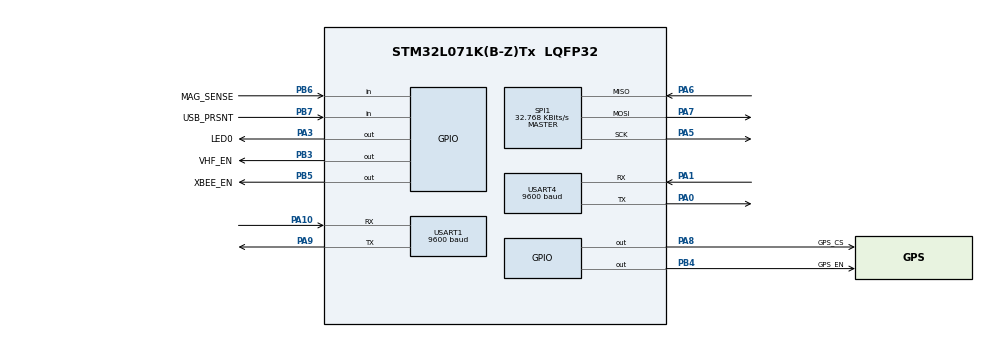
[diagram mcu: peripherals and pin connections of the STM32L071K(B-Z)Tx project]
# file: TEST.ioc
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Mcu.Family=STM32L0
Mcu.Name=STM32L071K(B-Z)Tx
Mcu.Package=LQFP32
NVIC.RTC_IRQn=true\:0\:0\:false\:false\:true\:true\:true
NVIC.SPI1_IRQn=true\:0\:0\:false\:false\:true\:true\:true
NVIC.TIM2_IRQn=true\:0\:0\:false\:false\:true\:true\:true
NVIC.USART1_IRQn=true\:0\:0\:false\:false\:true\:true\:true
NVIC.USART4_5_IRQn=true\:0\:0\:false\:false\:true\:true\:true
PA0.Mode=Asynchronous
PA0.Signal=USART4_TX
PA1.Mode=Asynchronous
PA1.Signal=USART4_RX
PA10.Mode=Asynchronous
PA10.Signal=USART1_RX
PA13.Mode=Serial_Wire
PA13.Signal=SYS_SWDIO
PA14.Mode=Serial_Wire
PA14.Signal=SYS_SWCLK
PA3.GPIO_Label=LED0
PA3.Signal=GPIO_Output
PA5.Mode=Full_Duplex_Master
PA5.Signal=SPI1_SCK
PA6.Mode=Full_Duplex_Master
PA6.Signal=SPI1_MISO
PA7.Mode=Full_Duplex_Master
PA7.Signal=SPI1_MOSI
PA8.GPIO_Label=GPS_CS
PA8.Signal=GPIO_Output
PA9.Mode=Asynchronous
PA9.Signal=USART1_TX
PB3.GPIO_Label=VHF_EN
PB3.Signal=GPIO_Output
PB4.GPIO_Label=GPS_EN
PB4.Signal=GPIO_Output
PB5.GPIO_Label=XBEE_EN
PB5.Signal=GPIO_Output
PB6.GPIO_Label=MAG_SENSE
PB6.Signal=GPIO_Input
PB7.GPIO_Label=USB_PRSNT
PB7.Signal=GPIO_Input
PC14-OSC32_IN.Mode=LSE-External-Oscillator
PC14-OSC32_IN.Signal=RCC_OSC32_IN
PC15-OSC32_OUT.Mode=LSE-External-Oscillator
PC15-OSC32_OUT.Signal=RCC_OSC32_OUT
ProjectManager.HeapSize=0x200
ProjectManager.StackSize=0x400
ProjectManager.TargetToolchain=MDK-ARM V5
RCC.AHBFreq_Value=262144
RCC.APB1Freq_Value=262144
RCC.APB1TimFreq_Value=262144
RCC.APB2Freq_Value=262144
RCC.APB2TimFreq_Value=262144
RCC.HCLKFreq_Value=262144
RCC.HSI16_VALUE=16000000
RCC.HSI_VALUE=16000000
RCC.MSIClockRange=RCC_MSIRANGE_2
RCC.MSI_VALUE=262144
RCC.RTCClockSelection=RCC_RTCCLKSOURCE_LSE
RCC.RTCClockSelectionVirtual=RCC_RTCCLKSOURCE_LSE
RCC.SYSCLKFreq_VALUE=262144
RCC.VCOOutputFreq_Value=48000000
RTC.Alarm=RTC_ALARM_A
SPI1.BaudRatePrescaler=SPI_BAUDRATEPRESCALER_8
SPI1.CalculateBaudRate=32.768 KBits/s
SPI1.Direction=SPI_DIRECTION_2LINES
SPI1.Mode=SPI_MODE_MASTER
SPI1.VirtualType=VM_MASTER
USART1.BaudRate=9600
USART1.VirtualMode-Asynchronous=VM_ASYNC
USART4.BaudRate=9600
USART4.SwapParam=ADVFEATURE_SWAP_ENABLE
USART4.VirtualMode-Asynchronous=VM_ASYNC
VP_RTC_VS_RTC_Activate.Mode=RTC_Enabled
VP_RTC_VS_RTC_Alarm_A_Intern.Mode=Alarm A
VP_RTC_VS_RTC_Calendar.Mode=RTC_Calendar
VP_TIM2_VS_ClockSourceINT.Mode=Internal
board=custom

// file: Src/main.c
/* USER CODE BEGIN Header */
/**
  ******************************************************************************
  * @file           : main.c
  * @brief          : Main program body
  ******************************************************************************
  * @attention
  *
  * <h2><center>&copy; Copyright (c) 2019 STMicroelectronics.
  * All rights reserved.</center></h2>
  *
  * This software component is licensed by ST under BSD 3-Clause license,
  * the "License"; You may not use this file except in compliance with the
  * License. You may obtain a copy of the License at:
  *                        opensource.org/licenses/BSD-3-Clause
  *
  ******************************************************************************
  */

#include "main.h"
#include "comport.h"
#include "globals.h"
#include "flash.h"
#include "xbee.h"
#include "timers.h"
#include "scheduler.h"
#include "lowpower.h"
#include <string.h>
int checkSchedule = 0;
int GPS_active = 0;
int XB_VHF_active = 0;

void SystemClock_Config(void);
static void MX_GPIO_Init(void);
static void MX_RTC_Init(void);
static void MX_SPI1_Init(void);
static void MX_TIM2_Init(void);
static void MX_USART1_UART_Init(void);
static void MX_USART4_UART_Init(void);

//Begin main
//------------------------------------------------------------------------------
int main(void)
	{
  //-- Initial MCU Configuration------------------------------------------------
  // Reset of all peripherals, Initializes the Flash interface and the Systick.
  LL_APB2_GRP1_EnableClock(LL_APB2_GRP1_PERIPH_SYSCFG);
  LL_APB1_GRP1_EnableClock(LL_APB1_GRP1_PERIPH_PWR);

  // Configure the system clock
  SystemClock_Config();

	__disable_irq();
  // Initialize all configured peripherals
  MX_GPIO_Init();
  MX_RTC_Init();
	RTC_initAlarm();
  MX_SPI1_Init();
  MX_TIM2_Init();
  MX_USART1_UART_Init();
	// Set up interrupts for the UART coms
	LL_USART_Disable(USART1);
	USART1->CR1 |= USART_CR1_RXNEIE;
	LL_USART_Enable(USART1);

#ifdef __LARGE_COLLAR_
  MX_USART4_UART_Init();
	LL_USART_Disable(USART4);
	USART4->CR1 |= USART_CR1_RXNEIE;
	LL_USART_Enable(USART4);
#endif

	// Enable these interrupts
	__enable_irq();

	// Init timers and alarms

	TIM2_init();

	//This small delay initializes the delay for further use
	TIM2_delay(1);

	//Ensure all devices are off
	GPS_GPSDisable();
	GPS_GPSCSHigh();
#ifdef __LARGE_COLLAR_
	XB_DisableXbee();
	VHF_DisableVHF();
#endif

	// Set unused pins low
	LPM_gpioInit();

	//-----------------
	// Main Variables
	// These vars are used as flags for the scheduler
	int GPS_active 	= 0;
	int XB_VHF_active 	= 0;

#ifndef __PRODUCTION_
	FLASH_Unlock();
	EEPROM_WriteByte(0x0A, 0x08080004);
	FLASH_Lock();
#endif

	//End of initialization, begin while loop
	//------------------------------------------------------------------------------
  while (1)
  {

		//Check for com port connected (should be while to hold device in this state)
		//----------------------------
		if(CC_ComPortPresent())
		{

			//Check for handshake from GUI
			if(CC_CheckForHandshake())
			{
				//Handshake completed, look for command, execute commands and loop
				while (CC_ComPortPresent())
				{
					CC_ExecuteCommand(CC_ParseCommand());
					break;
				}//While present
			}//Check handshake

		}//Comport present
		//Logic low hall effect sensor, this means no mag is present
		if( (MAG_SENSE_GPIO_Port->IDR & MAG_SENSE_Pin) != 0 )
		{
			if( checkSchedule == 1){
				scheduler( &GPS_active, &XB_VHF_active );
				checkSchedule = 0;
			}
			if(GPS_active)
			{
				GPS_subroutine();
				GPS_active = 0;
			}
#ifdef __LARGE_COLLAR_
			if(XB_VHF_active)
			{
				XB_XbeeSubroutine();
				VHF_EnableVHF();
				//May need to set sleep mode in a way that it will not disable this reg
			}
			else
			{
				VHF_DisableVHF();
			}
#endif
		}//Mag sense pin check
		else
		{
			LPM_stop();
			//__sleep() etc maybe ensure devices are disabled as well
		}

  }
}

void SystemClock_Config(void)
{
  LL_FLASH_SetLatency(LL_FLASH_LATENCY_0);

  if(LL_FLASH_GetLatency() != LL_FLASH_LATENCY_0)
  {
  Error_Handler();
  }
  LL_PWR_SetRegulVoltageScaling(LL_PWR_REGU_VOLTAGE_SCALE1);
  LL_RCC_MSI_Enable();

   /* Wait till MSI is ready */
  while(LL_RCC_MSI_IsReady() != 1)
  {

  }
  LL_RCC_MSI_SetRange(LL_RCC_MSIRANGE_2);
  LL_RCC_MSI_SetCalibTrimming(0);
  LL_PWR_EnableBkUpAccess();
  LL_RCC_ForceBackupDomainReset();
  LL_RCC_ReleaseBackupDomainReset();
  LL_RCC_LSE_SetDriveCapability(LL_RCC_LSEDRIVE_LOW);
  LL_RCC_LSE_Enable();

   /* Wait till LSE is ready */
  while(LL_RCC_LSE_IsReady() != 1)
  {

  }
  LL_RCC_SetRTCClockSource(LL_RCC_RTC_CLKSOURCE_LSE);
  LL_RCC_EnableRTC();
  LL_RCC_SetAHBPrescaler(LL_RCC_SYSCLK_DIV_1);
  LL_RCC_SetAPB1Prescaler(LL_RCC_APB1_DIV_1);
  LL_RCC_SetAPB2Prescaler(LL_RCC_APB2_DIV_1);
  LL_RCC_SetSysClkSource(LL_RCC_SYS_CLKSOURCE_MSI);

   /* Wait till System clock is ready */
  while(LL_RCC_GetSysClkSource() != LL_RCC_SYS_CLKSOURCE_STATUS_MSI)
  {

  }
  LL_Init1msTick(262144);
  LL_SYSTICK_SetClkSource(LL_SYSTICK_CLKSOURCE_HCLK);
  LL_SetSystemCoreClock(262144);
  LL_RCC_SetUSARTClockSource(LL_RCC_USART1_CLKSOURCE_PCLK2);
}

static void MX_RTC_Init(void)
{

  LL_RTC_InitTypeDef RTC_InitStruct = {0};
  LL_RTC_TimeTypeDef RTC_TimeStruct = {0};
  LL_RTC_DateTypeDef RTC_DateStruct = {0};

  /* Peripheral clock enable */
  LL_RCC_EnableRTC();

  /* RTC interrupt Init */
  NVIC_SetPriority(RTC_IRQn, 0);
  NVIC_EnableIRQ(RTC_IRQn);

  /** Initialize RTC and set the Time and Date
  */
  RTC_InitStruct.HourFormat = LL_RTC_HOURFORMAT_24HOUR;
  RTC_InitStruct.AsynchPrescaler = 127;
  RTC_InitStruct.SynchPrescaler = 255;
  LL_RTC_Init(RTC, &RTC_InitStruct);
  /** Initialize RTC and set the Time and Date
  */
  RTC_TimeStruct.Hours = 0;
  RTC_TimeStruct.Minutes = 0;
  RTC_TimeStruct.Seconds = 0;
  LL_RTC_TIME_Init(RTC, LL_RTC_FORMAT_BCD, &RTC_TimeStruct);
  RTC_DateStruct.WeekDay = LL_RTC_WEEKDAY_MONDAY;
  RTC_DateStruct.Month = LL_RTC_MONTH_JANUARY;
  RTC_DateStruct.Year = 0;
  LL_RTC_DATE_Init(RTC, LL_RTC_FORMAT_BCD, &RTC_DateStruct);
  /** Initialize RTC and set the Time and Date
  */

}

static void MX_SPI1_Init(void)
{

  LL_SPI_InitTypeDef SPI_InitStruct = {0};

  LL_GPIO_InitTypeDef GPIO_InitStruct = {0};

  /* Peripheral clock enable */
  LL_APB2_GRP1_EnableClock(LL_APB2_GRP1_PERIPH_SPI1);

  LL_IOP_GRP1_EnableClock(LL_IOP_GRP1_PERIPH_GPIOA);
  /**SPI1 GPIO Configuration
  PA5   ------> SPI1_SCK
  PA6   ------> SPI1_MISO
  PA7   ------> SPI1_MOSI
  */
  GPIO_InitStruct.Pin = LL_GPIO_PIN_5;
  GPIO_InitStruct.Mode = LL_GPIO_MODE_ALTERNATE;
  GPIO_InitStruct.Speed = LL_GPIO_SPEED_FREQ_VERY_HIGH;
  GPIO_InitStruct.OutputType = LL_GPIO_OUTPUT_PUSHPULL;
  GPIO_InitStruct.Pull = LL_GPIO_PULL_NO;
  GPIO_InitStruct.Alternate = LL_GPIO_AF_0;
  LL_GPIO_Init(GPIOA, &GPIO_InitStruct);

  GPIO_InitStruct.Pin = LL_GPIO_PIN_6;
  GPIO_InitStruct.Mode = LL_GPIO_MODE_ALTERNATE;
  GPIO_InitStruct.Speed = LL_GPIO_SPEED_FREQ_VERY_HIGH;
  GPIO_InitStruct.OutputType = LL_GPIO_OUTPUT_PUSHPULL;
  GPIO_InitStruct.Pull = LL_GPIO_PULL_NO;
  GPIO_InitStruct.Alternate = LL_GPIO_AF_0;
  LL_GPIO_Init(GPIOA, &GPIO_InitStruct);

  GPIO_InitStruct.Pin = LL_GPIO_PIN_7;
  GPIO_InitStruct.Mode = LL_GPIO_MODE_ALTERNATE;
  GPIO_InitStruct.Speed = LL_GPIO_SPEED_FREQ_VERY_HIGH;
  GPIO_InitStruct.OutputType = LL_GPIO_OUTPUT_PUSHPULL;
  GPIO_InitStruct.Pull = LL_GPIO_PULL_NO;
  GPIO_InitStruct.Alternate = LL_GPIO_AF_0;
  LL_GPIO_Init(GPIOA, &GPIO_InitStruct);

  /* SPI1 interrupt Init */
  NVIC_SetPriority(SPI1_IRQn, -5);
  NVIC_EnableIRQ(SPI1_IRQn);

  /* SPI1 parameter configuration*/
  SPI_InitStruct.TransferDirection = LL_SPI_FULL_DUPLEX;
  SPI_InitStruct.Mode = LL_SPI_MODE_MASTER;
  SPI_InitStruct.DataWidth = LL_SPI_DATAWIDTH_8BIT;
  SPI_InitStruct.ClockPolarity = LL_SPI_POLARITY_LOW;
  SPI_InitStruct.ClockPhase = LL_SPI_PHASE_1EDGE;
  SPI_InitStruct.NSS = LL_SPI_NSS_SOFT;
  SPI_InitStruct.BaudRate = LL_SPI_BAUDRATEPRESCALER_DIV8;
  SPI_InitStruct.BitOrder = LL_SPI_MSB_FIRST;
  SPI_InitStruct.CRCCalculation = LL_SPI_CRCCALCULATION_DISABLE;
  SPI_InitStruct.CRCPoly = 7;
  LL_SPI_Init(SPI1, &SPI_InitStruct);
  LL_SPI_SetStandard(SPI1, LL_SPI_PROTOCOL_MOTOROLA);
  /* USER CODE BEGIN SPI1_Init 2 */
	if((SPI1->CR1 & SPI_CR1_SPE) != SPI_CR1_SPE){
      // If disabled, I enable it
      SPI1->CR1 |= SPI_CR1_SPE;
  }
  /* USER CODE END SPI1_Init 2 */

}

static void MX_TIM2_Init(void)
{

  LL_TIM_InitTypeDef TIM_InitStruct = {0};

  /* Peripheral clock enable */
  LL_APB1_GRP1_EnableClock(LL_APB1_GRP1_PERIPH_TIM2);

  /* TIM2 interrupt Init */
  NVIC_SetPriority(TIM2_IRQn, -6);
  NVIC_EnableIRQ(TIM2_IRQn);

  TIM_InitStruct.Prescaler = 0;
  TIM_InitStruct.CounterMode = LL_TIM_COUNTERMODE_UP;
  TIM_InitStruct.Autoreload = 0;
  TIM_InitStruct.ClockDivision = LL_TIM_CLOCKDIVISION_DIV1;
  LL_TIM_Init(TIM2, &TIM_InitStruct);
  LL_TIM_DisableARRPreload(TIM2);
  LL_TIM_SetClockSource(TIM2, LL_TIM_CLOCKSOURCE_INTERNAL);
  LL_TIM_SetTriggerOutput(TIM2, LL_TIM_TRGO_RESET);
  LL_TIM_DisableMasterSlaveMode(TIM2);

}

static void MX_USART1_UART_Init(void)
{

  LL_USART_InitTypeDef USART_InitStruct = {0};

  LL_GPIO_InitTypeDef GPIO_InitStruct = {0};

  /* Peripheral clock enable */
  LL_APB2_GRP1_EnableClock(LL_APB2_GRP1_PERIPH_USART1);

  LL_IOP_GRP1_EnableClock(LL_IOP_GRP1_PERIPH_GPIOA);
  /**USART1 GPIO Configuration
  PA9   ------> USART1_TX
  PA10   ------> USART1_RX
  */
  GPIO_InitStruct.Pin = LL_GPIO_PIN_9;
  GPIO_InitStruct.Mode = LL_GPIO_MODE_ALTERNATE;
  GPIO_InitStruct.Speed = LL_GPIO_SPEED_FREQ_VERY_HIGH;
  GPIO_InitStruct.OutputType = LL_GPIO_OUTPUT_PUSHPULL;
  GPIO_InitStruct.Pull = LL_GPIO_PULL_NO;
  GPIO_InitStruct.Alternate = LL_GPIO_AF_4;
  LL_GPIO_Init(GPIOA, &GPIO_InitStruct);

  GPIO_InitStruct.Pin = LL_GPIO_PIN_10;
  GPIO_InitStruct.Mode = LL_GPIO_MODE_ALTERNATE;
  GPIO_InitStruct.Speed = LL_GPIO_SPEED_FREQ_VERY_HIGH;
  GPIO_InitStruct.OutputType = LL_GPIO_OUTPUT_PUSHPULL;
  GPIO_InitStruct.Pull = LL_GPIO_PULL_NO;
  GPIO_InitStruct.Alternate = LL_GPIO_AF_4;
  LL_GPIO_Init(GPIOA, &GPIO_InitStruct);

  /* USART1 interrupt Init */
  NVIC_SetPriority(USART1_IRQn, -7);
  NVIC_EnableIRQ(USART1_IRQn);

  USART_InitStruct.BaudRate = 9600;
  USART_InitStruct.DataWidth = LL_USART_DATAWIDTH_8B;
  USART_InitStruct.StopBits = LL_USART_STOPBITS_1;
  USART_InitStruct.Parity = LL_USART_PARITY_NONE;
  USART_InitStruct.TransferDirection = LL_USART_DIRECTION_TX_RX;
  USART_InitStruct.HardwareFlowControl = LL_USART_HWCONTROL_NONE;
  USART_InitStruct.OverSampling = LL_USART_OVERSAMPLING_16;
  LL_USART_Init(USART1, &USART_InitStruct);
  LL_USART_DisableOverrunDetect(USART1);
  LL_USART_ConfigAsyncMode(USART1);
  LL_USART_Enable(USART1);

}

static void MX_USART4_UART_Init(void)
{

  LL_USART_InitTypeDef USART_InitStruct = {0};

  LL_GPIO_InitTypeDef GPIO_InitStruct = {0};

  /* Peripheral clock enable */
  LL_APB1_GRP1_EnableClock(LL_APB1_GRP1_PERIPH_USART4);

  LL_IOP_GRP1_EnableClock(LL_IOP_GRP1_PERIPH_GPIOA);
  /**USART4 GPIO Configuration
  PA0   ------> USART4_TX
  PA1   ------> USART4_RX
  */
  GPIO_InitStruct.Pin = LL_GPIO_PIN_0;
  GPIO_InitStruct.Mode = LL_GPIO_MODE_ALTERNATE;
  GPIO_InitStruct.Speed = LL_GPIO_SPEED_FREQ_VERY_HIGH;
  GPIO_InitStruct.OutputType = LL_GPIO_OUTPUT_PUSHPULL;
  GPIO_InitStruct.Pull = LL_GPIO_PULL_NO;
  GPIO_InitStruct.Alternate = LL_GPIO_AF_6;
  LL_GPIO_Init(GPIOA, &GPIO_InitStruct);

  GPIO_InitStruct.Pin = LL_GPIO_PIN_1;
  GPIO_InitStruct.Mode = LL_GPIO_MODE_ALTERNATE;
  GPIO_InitStruct.Speed = LL_GPIO_SPEED_FREQ_VERY_HIGH;
  GPIO_InitStruct.OutputType = LL_GPIO_OUTPUT_PUSHPULL;
  GPIO_InitStruct.Pull = LL_GPIO_PULL_NO;
  GPIO_InitStruct.Alternate = LL_GPIO_AF_6;
  LL_GPIO_Init(GPIOA, &GPIO_InitStruct);

  /* USART4 interrupt Init */
  NVIC_SetPriority(USART4_5_IRQn, -3);
  NVIC_EnableIRQ(USART4_5_IRQn);

  USART_InitStruct.BaudRate = 9600;
  USART_InitStruct.DataWidth = LL_USART_DATAWIDTH_8B;
  USART_InitStruct.StopBits = LL_USART_STOPBITS_1;
  USART_InitStruct.Parity = LL_USART_PARITY_NONE;
  USART_InitStruct.TransferDirection = LL_USART_DIRECTION_TX_RX;
  USART_InitStruct.HardwareFlowControl = LL_USART_HWCONTROL_NONE;
  USART_InitStruct.OverSampling = LL_USART_OVERSAMPLING_16;
  LL_USART_Init(USART4, &USART_InitStruct);
  LL_USART_SetTXRXSwap(USART4, LL_USART_TXRX_SWAPPED);
  LL_USART_ConfigAsyncMode(USART4);
  LL_USART_Enable(USART4);

}

static void MX_GPIO_Init(void)
{
  LL_GPIO_InitTypeDef GPIO_InitStruct = {0};

  /* GPIO Ports Clock Enable */
  LL_IOP_GRP1_EnableClock(LL_IOP_GRP1_PERIPH_GPIOC);
  LL_IOP_GRP1_EnableClock(LL_IOP_GRP1_PERIPH_GPIOA);
  LL_IOP_GRP1_EnableClock(LL_IOP_GRP1_PERIPH_GPIOB);

  /**/
  LL_GPIO_ResetOutputPin(LED0_GPIO_Port, LED0_Pin);

  /**/
  LL_GPIO_ResetOutputPin(GPS_CS_GPIO_Port, GPS_CS_Pin);

  /**/
  LL_GPIO_ResetOutputPin(VHF_EN_GPIO_Port, VHF_EN_Pin);

  /**/
  LL_GPIO_ResetOutputPin(GPS_EN_GPIO_Port, GPS_EN_Pin);

  /**/
  LL_GPIO_ResetOutputPin(XBEE_EN_GPIO_Port, XBEE_EN_Pin);

  /**/
  GPIO_InitStruct.Pin = LED0_Pin;
  GPIO_InitStruct.Mode = LL_GPIO_MODE_OUTPUT;
  GPIO_InitStruct.Speed = LL_GPIO_SPEED_FREQ_LOW;
  GPIO_InitStruct.OutputType = LL_GPIO_OUTPUT_PUSHPULL;
  GPIO_InitStruct.Pull = LL_GPIO_PULL_NO;
  LL_GPIO_Init(LED0_GPIO_Port, &GPIO_InitStruct);

  /**/
  GPIO_InitStruct.Pin = GPS_CS_Pin;
  GPIO_InitStruct.Mode = LL_GPIO_MODE_OUTPUT;
  GPIO_InitStruct.Speed = LL_GPIO_SPEED_FREQ_LOW;
  GPIO_InitStruct.OutputType = LL_GPIO_OUTPUT_PUSHPULL;
  GPIO_InitStruct.Pull = LL_GPIO_PULL_NO;
  LL_GPIO_Init(GPS_CS_GPIO_Port, &GPIO_InitStruct);

  /**/
  GPIO_InitStruct.Pin = VHF_EN_Pin;
  GPIO_InitStruct.Mode = LL_GPIO_MODE_OUTPUT;
  GPIO_InitStruct.Speed = LL_GPIO_SPEED_FREQ_LOW;
  GPIO_InitStruct.OutputType = LL_GPIO_OUTPUT_PUSHPULL;
  GPIO_InitStruct.Pull = LL_GPIO_PULL_NO;
  LL_GPIO_Init(VHF_EN_GPIO_Port, &GPIO_InitStruct);

  /**/
  GPIO_InitStruct.Pin = GPS_EN_Pin;
  GPIO_InitStruct.Mode = LL_GPIO_MODE_OUTPUT;
  GPIO_InitStruct.Speed = LL_GPIO_SPEED_FREQ_LOW;
  GPIO_InitStruct.OutputType = LL_GPIO_OUTPUT_PUSHPULL;
  GPIO_InitStruct.Pull = LL_GPIO_PULL_NO;
  LL_GPIO_Init(GPS_EN_GPIO_Port, &GPIO_InitStruct);

  /**/
  GPIO_InitStruct.Pin = XBEE_EN_Pin;
  GPIO_InitStruct.Mode = LL_GPIO_MODE_OUTPUT;
  GPIO_InitStruct.Speed = LL_GPIO_SPEED_FREQ_LOW;
  GPIO_InitStruct.OutputType = LL_GPIO_OUTPUT_PUSHPULL;
  GPIO_InitStruct.Pull = LL_GPIO_PULL_NO;
  LL_GPIO_Init(XBEE_EN_GPIO_Port, &GPIO_InitStruct);

  /**/
  GPIO_InitStruct.Pin = MAG_SENSE_Pin;
  GPIO_InitStruct.Mode = LL_GPIO_MODE_INPUT;
  GPIO_InitStruct.Pull = LL_GPIO_PULL_NO;
  LL_GPIO_Init(MAG_SENSE_GPIO_Port, &GPIO_InitStruct);

  /**/
  GPIO_InitStruct.Pin = USB_PRSNT_Pin;
  GPIO_InitStruct.Mode = LL_GPIO_MODE_INPUT;
  GPIO_InitStruct.Pull = LL_GPIO_PULL_NO;
  LL_GPIO_Init(USB_PRSNT_GPIO_Port, &GPIO_InitStruct);

	/**/
  GPIO_InitStruct.Pin = LOW_BATT_Pin;
  GPIO_InitStruct.Mode = LL_GPIO_MODE_INPUT;
  GPIO_InitStruct.Pull = LL_GPIO_PULL_NO;
  LL_GPIO_Init(LOW_BATT_GPIO_Port, &GPIO_InitStruct);

}

void Error_Handler(void)
{
}

/************************ (C) COPYRIGHT STMicroelectronics *****END OF FILE****/
